# f29h85x_c29_secure_regs register map
Vendor: Texas Instruments
Peripheral module from a debugger description file (folder C29).
Registers are 32-bit, read-write, no defined reset value unless marked. A register's access mark holds for its fields unless they carry their own. Offsets are as the file gives them; lines under a group give offsets from that group; [hi:lo] are bit positions; {n}, {i} and the like mark numbered series; 'fields as' and 'values as' point back to an identical list; <NAME> marks a mode.

## C29_SECURE_REGS — C29 SECURE Registers
{0x0+4i} SECSP{i} (i=0..7) — Secure Stackpointer {i}
  [31:0] SP{i} — Stack pointer {i}
0x80 PSP ro — Protected call stack pointer
  [11:0] PSP
0x84 WARNPSP — Warning level register for protected call stack pointer
  [11:0] WARNPSP — Warning level for protected call stack pointer
0x88 MAXPSP ro — Maximum levels of protected calls supported by the HW
  [11:0] MAXPSP
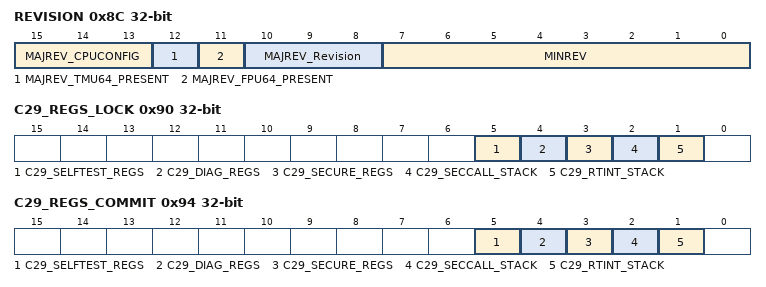
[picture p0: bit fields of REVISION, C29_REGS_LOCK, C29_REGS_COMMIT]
0x8C REVISION ro — IP revision id register
  [15:13] MAJREV_CPUCONFIG — CPU configuration
  [12] MAJREV_TMU64_PRESENT — TMU64 Present
  [11] MAJREV_FPU64_PRESENT — FPU64 Present
  [10:8] MAJREV_Revision — Major Revision Number
  [7:0] MINREV — Minor Revision Number
0x90 C29_REGS_LOCK — Lock register
  [5] C29_SELFTEST_REGS — C29 Selftest registers Lock
  [4] C29_DIAG_REGS — C29 DIAG registers Lock
  [3] C29_SECURE_REGS — C29 SECURE registers Lock
  [2] C29_SECCALL_STACK — C29 SECCALL stack registers Lock
  [1] C29_RTINT_STACK — C29 RTINT stack registers Lock
0x94 C29_REGS_COMMIT — Commit register
  [5] C29_SELFTEST_REGS — C29 Selftest registers Commit
  [4] C29_DIAG_REGS — C29 DIAG registers Commit
  [3] C29_SECURE_REGS — C29 SECURE registers Commit
  [2] C29_SECCALL_STACK — C29 SECCALL stack registers Commit
  [1] C29_RTINT_STACK — C29 RTINT stack registers Commit
